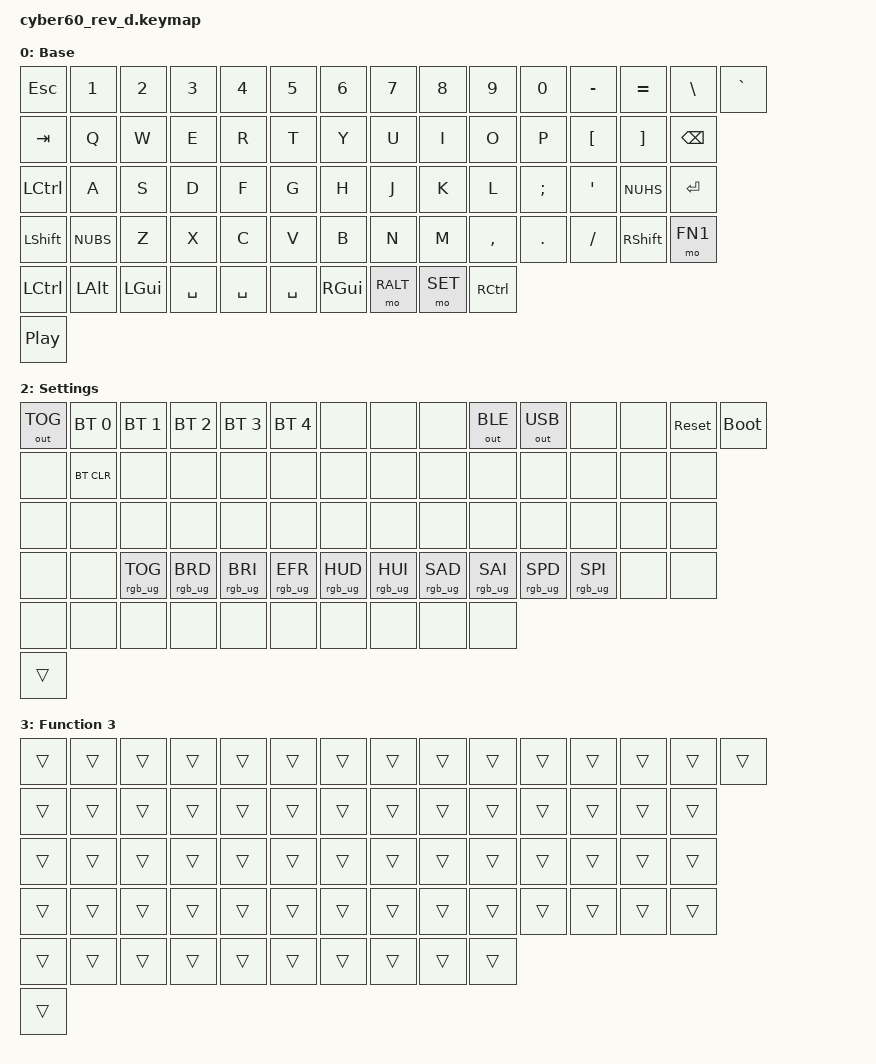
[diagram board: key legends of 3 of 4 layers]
#include <behaviors.dtsi>
#include <dt-bindings/zmk/bt.h>
#include <dt-bindings/zmk/keys.h>
#include <dt-bindings/zmk/rgb.h>
#include <dt-bindings/zmk/outputs.h>

#define FN1 1
#define SET 2

/ {
    keymap {
        compatible = "zmk,keymap";
        default_layer {
            // Base layer
            // -------------------------------------------------------------------------------------------
            // | ESC |  1  |  2  |  3  |  4  |  5  |  6  |  7  |  8  |  9  |  0  |  -  |  =  | "\" |GRAVE|
            // |  TAB |  Q  |  W  |  E  |  R  |  T  |  Y  |  U  |  I  |  O  |  P  |  [  |  ]  |   "\"    |
            // | CAPS  |  A  |  S  |  D  |  F  |  G  |  H  |  J  |  K  |  L  |  ;  |  '  |NUHS| ENTER    |
            // | SHIFT |NUBS| Z |  X  |  C  |  V  |  B  |  N  |  M  |  ,  |  .  |  /  |    Shift   | FN  |
            // |  LCTL  |  LWIN  |  LALT  | SPACE  | SPACE |    SPACE   |  RALT | FN  |   RWIN  | RCTRL  |
            // | Rotary | (<-- Rotary switch) ------------------------------------------------------------ 
            display-name = "Base";
            bindings = <
            &kp ESC		&kp N1		&kp N2		&kp N3		&kp N4		&kp N5     &kp N6   &kp N7    &kp N8     &kp N9		&kp N0  	&kp MINUS	&kp EQUAL	&kp BSLH  &kp GRAVE
            &kp TAB     &kp Q		&kp W		&kp E		&kp R		&kp T      &kp Y    &kp U     &kp I      &kp O		&kp P   	&kp LBKT	&kp RBKT	&kp BKSP
            &kp LCTL	&kp A		&kp S		&kp D		&kp F		&kp G      &kp H    &kp J     &kp K      &kp L		&kp SEMI	&kp SQT		&kp NUHS	&kp RET
            &kp LSHFT	&kp NUBS	&kp Z		&kp X		&kp C		&kp V      &kp B    &kp N     &kp M  	 &kp COMMA  &kp DOT   	&kp FSLH	&kp RSHFT   &mo FN1
            &kp LCTRL	&kp LALT	&kp LGUI	&kp SPACE	&kp SPACE	&kp SPACE  &kp RGUI &mo RALT  &mo SET    &kp RCTRL
            &kp C_PP
            >;

            sensor-bindings = <&inc_dec_kp C_VOL_UP C_VOL_DN>;
        };

        fn_layer_0 {
            display-name = "Function 1";
            // Function layer
            // ------------------------------------------------------------------------------------------
            // | RESET | F1 |  F2 |  F3 |  F4 |  F5 |  F6 |  F7 |  F8 |  F9 | F10 | F11 | F12 |TRNS | DEL |
            // |BT_CLR |TRNS | UP  | BT0 | BT1 | BT2 | BT3 | BT4 | TRNS | TRNS | TRNS | TRNS | TRNS | TRNS|
            // | BOOTL  |LEFT |DOWN |RIGHT|TRNS |TRNS |TRNS | TRNS| TRNS |TRNS| TRNS |TRNS | TRNS | TRNS  |
            // |S_UNLK|TRNS|TRNS|TRNS|TRNS | TRNS| TRNS | TRNS |  TRNS| TRNS | TRNS| TRNS |   TRNS   |TRNS|
            // |  TRNS | TRNS | TRNS |      TRNS      | TRNS |     TRNS     |  TRNS |  TRNS | TRNS | TRNS |
            // | Rotary | (<-- Rotary switch) ----------------------------------------------------------- 

            bindings = <
            &trans   &kp F1		  &kp F2          &kp F3          &kp F4          &kp F5          &kp F6          &kp F7          &kp F8  		  &kp F9    &kp F10         &kp F11   &kp F12 &kp INS  &kp DEL
	        &kp CAPS &trans		  &trans          &trans          &trans          &trans          &trans          &trans          &trans  		  &kp SLCK  &kp PAUSE_BREAK &kp UP    &trans  &trans
	        &trans   &kp C_VOL_DN &kp C_VOL_UP    &kp K_MUTE      &trans          &trans          &trans          &trans          &kp HOME  	  &kp PG_UP &kp LEFT        &kp RIGHT &trans  &trans
            &trans	 &trans		  &rgb_ug RGB_TOG &rgb_ug RGB_BRI &rgb_ug RGB_EFR &rgb_ug RGB_HUD &rgb_ug RGB_HUI &rgb_ug RGB_SAD &rgb_ug RGB_SAI &kp END   &kp PG_DN       &kp DOWN  &trans  &trans
            &trans	 &trans		  &trans          &trans          &trans          &trans          &trans          &trans
            &kp C_PP
            >;

            sensor-bindings = <&inc_dec_kp C_VOL_UP C_VOL_DN>;
        };
        fn_layer_1 {
            display-name = "Settings";
            bindings = <
            &out OUT_TOG &bt BT_SEL 0 &bt BT_SEL 1    &bt BT_SEL 2    &bt BT_SEL 3    &bt BT_SEL 4    &none           &none           &none           &out OUT_BLE	  &out OUT_USB    &none           &none &sys_reset &bootloader
            &none        &bt BT_CLR   &none           &none           &none           &none           &none           &none           &none           &none           &none           &none           &none &none
            &none        &none        &none           &none           &none           &none           &none           &none           &none           &none           &none           &none           &none &none
            &none	     &none	      &rgb_ug RGB_TOG &rgb_ug RGB_BRD &rgb_ug RGB_BRI &rgb_ug RGB_EFR &rgb_ug RGB_HUD &rgb_ug RGB_HUI &rgb_ug RGB_SAD &rgb_ug RGB_SAI &rgb_ug RGB_SPD &rgb_ug RGB_SPI &none &none
            &none        &none        &none           &none           &none           &none           &none           &none           &none           &none   
            &trans
            >;

            sensor-bindings = <&inc_dec_kp C_VOL_UP C_VOL_DN>;
        };
        fn_layer_2 {
            display-name = "Function 3";
            bindings = <
            &trans	&trans  &trans  &trans  &trans  &trans  &trans  &trans  &trans  &trans  &trans  &trans  &trans  &trans  &trans
            &trans	&trans  &trans  &trans  &trans  &trans  &trans  &trans  &trans  &trans  &trans  &trans  &trans  &trans
            &trans	&trans  &trans  &trans  &trans  &trans  &trans  &trans  &trans  &trans  &trans  &trans  &trans  &trans
            &trans  &trans  &trans	&trans	&trans	&trans	&trans	&trans	&trans  &trans  &trans  &trans  &trans  &trans
            &trans  &trans  &trans  &trans  &trans  &trans  &trans  &trans  &trans  &trans
            &trans
            >;

            sensor-bindings = <&inc_dec_kp C_VOL_UP C_VOL_DN>;
        };
    };
};
